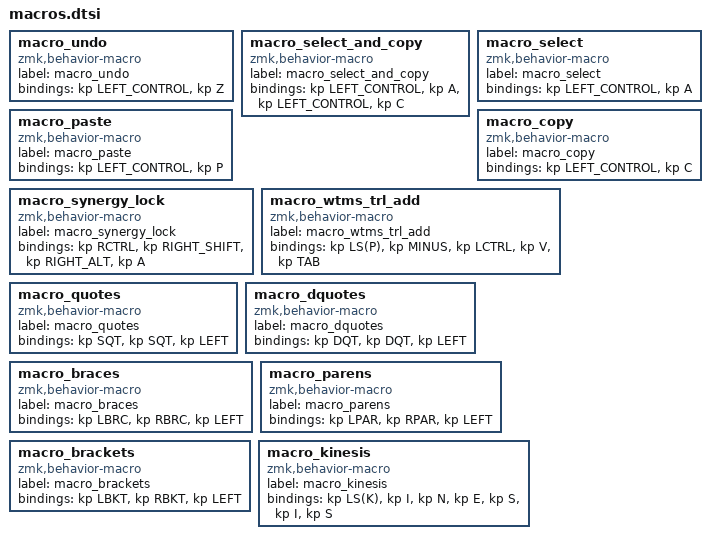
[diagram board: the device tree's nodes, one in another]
macro_undo: macro_undo{
compatible = "zmk,behavior-macro";
label = "macro_undo";
#binding-cells = <0>;
bindings = <&kp LEFT_CONTROL>, <&kp Z>;
};
macro_select_and_copy: macro_select_and_copy{
compatible = "zmk,behavior-macro";
label = "macro_select_and_copy";
#binding-cells = <0>;
bindings = <&kp LEFT_CONTROL>, <&kp A>, <&kp LEFT_CONTROL>, <&kp C>;
};
macro_select: macro_select{
compatible = "zmk,behavior-macro";
label = "macro_select";
#binding-cells = <0>;
bindings = <&kp LEFT_CONTROL>, <&kp A>;
};
macro_paste: macro_paste{
compatible = "zmk,behavior-macro";
label = "macro_paste";
#binding-cells = <0>;
bindings = <&kp LEFT_CONTROL>, <&kp P>;
};
macro_copy: macro_copy{
compatible = "zmk,behavior-macro";
label = "macro_copy";
#binding-cells = <0>;
bindings = <&kp LEFT_CONTROL>, <&kp C>;
};
macro_synergy_lock: macro_synergy_lock{
compatible = "zmk,behavior-macro";
label = "macro_synergy_lock";
#binding-cells = <0>;
bindings = <&kp RCTRL>, <&kp RIGHT_SHIFT>, <&kp RIGHT_ALT>, <&kp A>;
};
macro_wtms_trl_add: macro_wtms_trl_add{
compatible = "zmk,behavior-macro";
label = "macro_wtms_trl_add";
#binding-cells = <0>;
bindings = <&kp LS(P)>, <&kp MINUS>, <&kp LCTRL>, <&kp V>, <&kp TAB>;
};
macro_quotes: macro_quotes{
compatible = "zmk,behavior-macro";
label = "macro_quotes";
#binding-cells = <0>;
bindings = <&kp SQT>, <&kp SQT>, <&kp LEFT>;
};
macro_dquotes: macro_dquotes{
compatible = "zmk,behavior-macro";
label = "macro_dquotes";
#binding-cells = <0>;
bindings = <&kp DQT>, <&kp DQT>, <&kp LEFT>;
};
macro_braces: macro_braces{
compatible = "zmk,behavior-macro";
label = "macro_braces";
#binding-cells = <0>;
bindings = <&kp LBRC>, <&kp RBRC>, <&kp LEFT>;
};
macro_parens: macro_parens{
compatible = "zmk,behavior-macro";
label = "macro_parens";
#binding-cells = <0>;
bindings = <&kp LPAR>, <&kp RPAR>, <&kp LEFT>;
};
macro_brackets: macro_brackets{
compatible = "zmk,behavior-macro";
label = "macro_brackets";
#binding-cells = <0>;
bindings = <&kp LBKT>, <&kp RBKT>, <&kp LEFT>;
};
macro_kinesis: macro_kinesis{
compatible = "zmk,behavior-macro";
label = "macro_kinesis";
#binding-cells = <0>;
bindings = <&kp LS(K)>, <&kp I>, <&kp N>, <&kp E>, <&kp S>, <&kp I>, <&kp S>;
};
